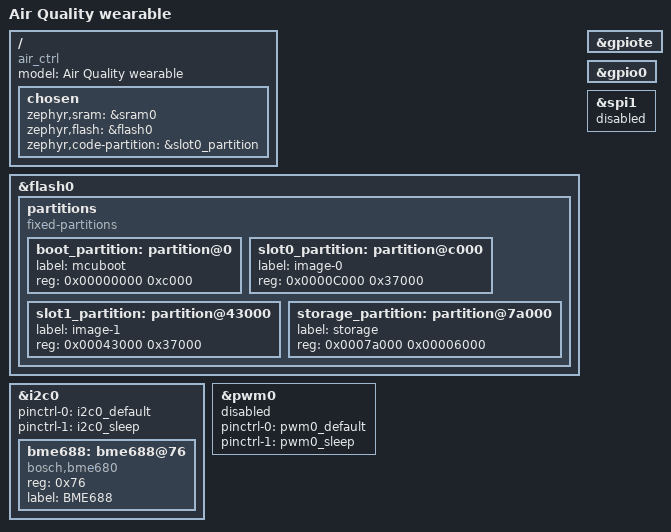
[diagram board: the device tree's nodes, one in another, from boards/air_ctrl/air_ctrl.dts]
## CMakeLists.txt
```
cmake_minimum_required(VERSION 3.20.0)

set(BOARD_ROOT ${CMAKE_CURRENT_SOURCE_DIR})

find_package(Zephyr REQUIRED HINTS $ENV{ZEPHYR_BASE})

project(air_ctrl)

# Application sources
target_sources(app PRIVATE
    src/main.c
    src/air_ctrl_bt.c
)

target_include_directories(app PRIVATE
    ${CMAKE_CURRENT_SOURCE_DIR}/src
)

if(CONFIG_AIR_CTRL_USE_BSEC)
    set(BSEC_INC_DIR ${CMAKE_CURRENT_SOURCE_DIR}/ext/algo/bsec_IAQ_Sel/inc)
    set(BSEC_CFG_DIR ${CMAKE_CURRENT_SOURCE_DIR}/ext/algo/bsec_IAQ_Sel/config/bme688/bme688_sel_33v_3s_28d)
    set(BSEC_SEL_C ${BSEC_CFG_DIR}/bsec_selectivity.c)
    set(BSEC_LIB ${CMAKE_CURRENT_SOURCE_DIR}/ext/algo/bsec_IAQ_Sel/bin/gcc/Cortex_M4F/libalgobsec.a)

    if(NOT EXISTS ${BSEC_LIB})
        message(FATAL_ERROR "CONFIG_AIR_CTRL_USE_BSEC is enabled but BSEC library was not found at: ${BSEC_LIB}")
    endif()

    target_sources(app PRIVATE
        src/air_ctrl_sensor_bsec.c
        ${BSEC_SEL_C}
    )

    target_include_directories(app PRIVATE
        ${BSEC_INC_DIR}
        ${BSEC_CFG_DIR}
    )

    target_link_libraries(app PRIVATE
        ${BSEC_LIB}
    )
else()
    target_sources(app PRIVATE
        src/air_ctrl_sensor_raw.c
    )
endif()
```

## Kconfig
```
source "Kconfig.zephyr"

menu "Air Ctrl"

config AIR_CTRL_USE_BSEC
	bool "Use Bosch BSEC library"
	default n

endmenu
```

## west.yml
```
manifest:
  version: "1.2"

  remotes:
    - name: zephyrproject-rtos
      url-base: https://github.com/zephyrproject-rtos

  projects:
    - name: zephyr
      remote: zephyrproject-rtos
      revision: v4.2.0
      path: zephyr
      import: true

  self:
    path: .
```

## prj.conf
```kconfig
# Debug console and logging
CONFIG_CONSOLE=y
CONFIG_LOG=y
CONFIG_STDOUT_CONSOLE=y
CONFIG_USE_SEGGER_RTT=y
CONFIG_RTT_CONSOLE=y
CONFIG_LOG_BACKEND_RTT=y
CONFIG_LOG_DEFAULT_LEVEL=3
CONFIG_CBPRINTF_FP_SUPPORT=y

CONFIG_SEGGER_RTT_BUFFER_SIZE_UP=8192
CONFIG_SEGGER_RTT_BUFFER_SIZE_DOWN=4096
CONFIG_LOG_MODE_DEFERRED=y
CONFIG_LOG_PROCESS_THREAD=y
CONFIG_LOG_PROCESS_THREAD_STACK_SIZE=2048

CONFIG_I2C=y

# Zephyr sensor subsystem + BME680 driver (used to read BME688 via compatible = "bosch,bme680")
CONFIG_SENSOR=y
CONFIG_BME680=y

# BME680 driver settings (compile-time)
CONFIG_BME680_TEMP_OVER_2X=y
CONFIG_BME680_PRESS_OVER_16X=y
CONFIG_BME680_HUMIDITY_OVER_1X=y
CONFIG_BME680_FILTER_OFF=y
CONFIG_BME680_HEATR_TEMP_LP=y
CONFIG_BME680_HEATR_DUR_LP=y

# FPU support and other stuff (required for BSEC library)
CONFIG_FPU=y
CONFIG_MAIN_STACK_SIZE=4096
CONFIG_PICOLIBC=y

# Bluetooth
CONFIG_BT=y
CONFIG_BT_PERIPHERAL=y
CONFIG_BT_DEVICE_NAME="air-ctrl"

CONFIG_SETTINGS=y
CONFIG_BT_SETTINGS=y

CONFIG_FLASH=y
CONFIG_FLASH_MAP=y
CONFIG_NVS=y
```

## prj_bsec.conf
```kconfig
CONFIG_AIR_CTRL_USE_BSEC=y
```

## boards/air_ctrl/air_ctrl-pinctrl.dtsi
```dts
&pinctrl {
	i2c0_default: i2c0_default {
		group1 {
			psels = <NRF_PSEL(TWIM_SDA, 0, 27)>,
			        <NRF_PSEL(TWIM_SCL, 0, 26)>;
		};
	};

	i2c0_sleep: i2c0_sleep {
		group1 {
			psels = <NRF_PSEL(TWIM_SDA, 0, 27)>,
			        <NRF_PSEL(TWIM_SCL, 0, 26)>;
			low-power-enable;
		};
	};

	pwm0_default: pwm0_default {
		group1 {
			psels = <NRF_PSEL(PWM_OUT0, 0, 10)>;
		};
	};

	pwm0_sleep: pwm0_sleep {
		group1 {
			psels = <NRF_PSEL(PWM_OUT0, 0, 10)>;
			low-power-enable;
		};
	};
};
```

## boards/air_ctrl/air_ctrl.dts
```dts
/dts-v1/;
#include <nordic/nrf52832_qfaa.dtsi>
#include "air_ctrl-pinctrl.dtsi"

/ {
	model = "Air Quality wearable";
	compatible = "air_ctrl";

	chosen {
		zephyr,sram = &sram0;
		zephyr,flash = &flash0;
		zephyr,code-partition = &slot0_partition;
	};
};

&flash0 {
	partitions {
		compatible = "fixed-partitions";
		#address-cells = <1>;
		#size-cells = <1>;

		boot_partition: partition@0 {
			label = "mcuboot";
			reg = <0x00000000 0xc000>;
		};

		slot0_partition: partition@c000 {
			label = "image-0";
			reg = <0x0000C000 0x37000>;
		};

		slot1_partition: partition@43000 {
			label = "image-1";
			reg = <0x00043000 0x37000>;
		};

		storage_partition: partition@7a000 {
			label = "storage";
			reg = <0x0007a000 0x00006000>;
		};
	};
};

&gpiote {
    status = "okay";
};

&gpio0 {
    status = "okay";
};

&i2c0 {
	status = "okay";
	pinctrl-0 = <&i2c0_default>;
	pinctrl-1 = <&i2c0_sleep>;
	pinctrl-names = "default", "sleep";

	bme688: bme688@76 {
		compatible = "bosch,bme680";
		reg = <0x76>;
		label = "BME688";
	};
};

&spi1 {
	status = "disabled";
};

&pwm0 {
	/* DISABLED: Pin conflict with backlight GPIO on P0.10 */
	status = "disabled";
	pinctrl-0 = <&pwm0_default>;
	pinctrl-1 = <&pwm0_sleep>;
	pinctrl-names = "default", "sleep";
};
```

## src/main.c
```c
#include <zephyr/kernel.h>
#include <zephyr/logging/log.h>
#include <zephyr/sys/util.h>

#include "air_ctrl_sensor.h"
#include "air_ctrl_bt.h"

LOG_MODULE_REGISTER(app, LOG_LEVEL_INF);

int main(void)
{
	int err;
	air_ctrl_sensor_data_t sensor_data;

	err = air_ctrl_bt_init();
	if (err) {
		LOG_ERR("Bluetooth init failed: %d", err);
	}

	LOG_INF("Air-ctrl device starting...");

	err = air_ctrl_sensor_init();
	if (err != 0) {
		LOG_ERR("Sensor integration init failed: %d", err);
		return 0;
	}

	#if IS_ENABLED(CONFIG_AIR_CTRL_USE_BSEC)
	LOG_INF("BSEC initialized, starting sensor loop...");
	LOG_INF("Note: IAQ accuracy will improve over time (needs ~5 min warm-up)");
	#else
	LOG_INF("Raw sensor mode initialized, starting sensor loop...");
	#endif

	while (true) {
		if (air_ctrl_sensor_run(&sensor_data)) {
			#if IS_ENABLED(CONFIG_AIR_CTRL_USE_BSEC)
			LOG_INF(
				"ts_ns,temp_raw_c,temp_comp_c,hum_raw_rh,hum_comp_rh,press_raw_pa,gas_raw_ohm,iaq,iaq_acc,static_iaq,co2_eq_ppm,breath_voc_eq_ppm,gas_pct,stabilized,run_in"
			);
			LOG_INF(
				"%lld,%.2f,%.2f,%.2f,%.2f,%.0f,%.0f,%.1f,%u,%.1f,%.0f,%.3f,%.1f,%u,%u",
				(long long)sensor_data.timestamp_ns,
				sensor_data.raw_temperature,
				sensor_data.temperature,
				sensor_data.raw_humidity,
				sensor_data.humidity,
				sensor_data.raw_pressure,
				sensor_data.raw_gas_resistance,
				sensor_data.iaq,
				sensor_data.iaq_accuracy,
				sensor_data.static_iaq,
				sensor_data.co2_equivalent,
				sensor_data.breath_voc_equivalent,
				sensor_data.gas_percentage,
				sensor_data.stabilization_status > 0.5f ? 1U : 0U,
				sensor_data.run_in_status > 0.5f ? 1U : 0U
			);
			#else
			LOG_INF("=== BME688 Raw Data ===");
			LOG_INF("  Temperature: %.2f \u00b0C", sensor_data.raw_temperature);
			LOG_INF("  Humidity: %.2f %%RH", sensor_data.raw_humidity);
			LOG_INF("  Pressure: %.2f hPa", sensor_data.raw_pressure / 100.0);
			LOG_INF("  Gas Resistance: %.0f Ohm", sensor_data.raw_gas_resistance);
			#endif

			(void)air_ctrl_bt_notify_sensor_data(&sensor_data);
		}

		k_sleep(K_MSEC(100));
	}
}
```

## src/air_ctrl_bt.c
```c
#include <zephyr/kernel.h>
#include <zephyr/settings/settings.h>
#include <zephyr/logging/log.h>
#include <zephyr/bluetooth/bluetooth.h>
#include <zephyr/bluetooth/conn.h>
#include <zephyr/bluetooth/gatt.h>
#include <zephyr/bluetooth/hci.h>
#include <zephyr/sys/byteorder.h>
#include <zephyr/sys/util.h>

#include <errno.h>
#include <limits.h>
#include <string.h>

#include "air_ctrl_bt.h"

LOG_MODULE_REGISTER(air_ctrl_bt, LOG_LEVEL_INF);

struct __packed air_ctrl_ble_sample_v1 {
	uint8_t version;
	uint8_t flags;
	uint16_t seq;
	uint32_t timestamp_ms;
	int16_t temp_c_x100;
	uint16_t hum_rh_x100;
	uint32_t gas_ohm;
	uint16_t iaq_x10;
	uint8_t iaq_acc;
	uint16_t co2_eq_ppm;
	uint16_t breath_voc_eq_ppb;
};

static struct bt_conn *default_conn;
static bool notify_enabled;
static uint16_t sample_seq;

static uint8_t last_sample[sizeof(struct air_ctrl_ble_sample_v1)];
static size_t last_sample_len;

#define BT_UUID_AIR_CTRL_SERVICE BT_UUID_DECLARE_128(BT_UUID_128_ENCODE(0x7f5f2cc2, 0x5d7a, 0x4a34, 0xa8c8, 0x1c7e3c01a7e1))

#define BT_UUID_AIR_CTRL_SAMPLE BT_UUID_DECLARE_128(BT_UUID_128_ENCODE(0x7f5f2cc3, 0x5d7a, 0x4a34, 0xa8c8, 0x1c7e3c01a7e1))

static void ccc_cfg_changed(const struct bt_gatt_attr *attr, uint16_t value)
{
	notify_enabled = (value == BT_GATT_CCC_NOTIFY);
}

static ssize_t read_sample(struct bt_conn *conn, const struct bt_gatt_attr *attr, void *buf,
			   uint16_t len, uint16_t offset)
{
	return bt_gatt_attr_read(conn, attr, buf, len, offset, last_sample, last_sample_len);
}

BT_GATT_SERVICE_DEFINE(air_ctrl_svc,
	BT_GATT_PRIMARY_SERVICE(BT_UUID_AIR_CTRL_SERVICE),
	BT_GATT_CHARACTERISTIC(BT_UUID_AIR_CTRL_SAMPLE,
			       BT_GATT_CHRC_READ | BT_GATT_CHRC_NOTIFY,
			       BT_GATT_PERM_READ, read_sample, NULL, NULL),
	BT_GATT_CCC(ccc_cfg_changed, BT_GATT_PERM_READ | BT_GATT_PERM_WRITE)
);

static const struct bt_data ad[] = {
	BT_DATA_BYTES(BT_DATA_FLAGS, (BT_LE_AD_GENERAL | BT_LE_AD_NO_BREDR)),
	BT_DATA(BT_DATA_NAME_COMPLETE, CONFIG_BT_DEVICE_NAME, sizeof(CONFIG_BT_DEVICE_NAME) - 1),
};

static void connected(struct bt_conn *conn, uint8_t err)
{
	if (err) {
		LOG_ERR("Connection failed err 0x%02x %s", err, bt_hci_err_to_str(err));
	} else {
		if (default_conn == NULL) {
			default_conn = bt_conn_ref(conn);
		}
		LOG_INF("Connected");
	}
}

static void disconnected(struct bt_conn *conn, uint8_t reason)
{
	if (default_conn != NULL) {
		bt_conn_unref(default_conn);
		default_conn = NULL;
	}

	notify_enabled = false;
	LOG_INF("Disconnected, reason 0x%02x %s", reason, bt_hci_err_to_str(reason));
}

BT_CONN_CB_DEFINE(conn_callbacks) = {
	.connected = connected,
	.disconnected = disconnected,
};

static void bt_ready(void)
{
	int err;

	LOG_INF("Bluetooth initialized");

	if (IS_ENABLED(CONFIG_SETTINGS)) {
		settings_load();
	}

	err = bt_le_adv_start(BT_LE_ADV_CONN_FAST_1, ad, ARRAY_SIZE(ad), NULL, 0);

	if (err) {
		LOG_ERR("Advertising failed to start (err %d)", err);
	} else {
		LOG_INF("Advertising successfully started");
	}
}

int air_ctrl_bt_init(void)
{
	int err;

	err = bt_enable(NULL);
	if (err) {
		LOG_ERR("Bluetooth init failed (err %d)", err);
		return err;
	}

	bt_ready();
	return 0;
}

bool air_ctrl_bt_is_connected(void)
{
	return default_conn != NULL;
}

static uint32_t ns_to_ms_u32(int64_t timestamp_ns)
{
	if (timestamp_ns <= 0) {
		return 0U;
	}

	return (uint32_t)(timestamp_ns / 1000000LL);
}

int air_ctrl_bt_notify_sensor_data(const air_ctrl_sensor_data_t *data)
{
	struct air_ctrl_ble_sample_v1 sample;
	uint16_t iaq_x10;
	uint32_t gas_ohm;
	uint16_t hum_x100;
	int16_t temp_x100;
	uint16_t co2_eq_ppm;
	uint16_t breath_voc_eq_ppb;

	if (data == NULL) {
		return -EINVAL;
	}

	if (!air_ctrl_bt_is_connected()) {
		return -ENOTCONN;
	}

	if (!notify_enabled) {
		return -EACCES;
	}

	gas_ohm = (data->raw_gas_resistance <= 0.0f) ? 0U : (uint32_t)data->raw_gas_resistance;

	temp_x100 = (int16_t)CLAMP((int32_t)(data->raw_temperature * 100.0f), INT16_MIN, INT16_MAX);
	hum_x100 = (uint16_t)CLAMP((int32_t)(data->raw_humidity * 100.0f), 0, UINT16_MAX);

	iaq_x10 = (data->iaq <= 0.0f) ? 0U : (uint16_t)CLAMP((int32_t)(data->iaq * 10.0f), 0, UINT16_MAX);
	co2_eq_ppm = (data->co2_equivalent <= 0.0f) ? 0U :
		(uint16_t)CLAMP((int32_t)(data->co2_equivalent + 0.5f), 0, UINT16_MAX);
	breath_voc_eq_ppb = (data->breath_voc_equivalent <= 0.0f) ? 0U :
		(uint16_t)CLAMP((int32_t)(data->breath_voc_equivalent * 1000.0f + 0.5f), 0, UINT16_MAX);

	sample.version = 2U;
	sample.flags = 0U;
	sample.seq = sys_cpu_to_le16(sample_seq++);
	sample.timestamp_ms = sys_cpu_to_le32(ns_to_ms_u32(data->timestamp_ns));
	sample.temp_c_x100 = (int16_t)sys_cpu_to_le16((uint16_t)temp_x100);
	sample.hum_rh_x100 = sys_cpu_to_le16(hum_x100);
	sample.gas_ohm = sys_cpu_to_le32(gas_ohm);
	sample.iaq_x10 = sys_cpu_to_le16(iaq_x10);
	sample.iaq_acc = data->iaq_accuracy;
	sample.co2_eq_ppm = sys_cpu_to_le16(co2_eq_ppm);
	sample.breath_voc_eq_ppb = sys_cpu_to_le16(breath_voc_eq_ppb);

	memcpy(last_sample, &sample, sizeof(sample));
	last_sample_len = sizeof(sample);

	return bt_gatt_notify(default_conn, &air_ctrl_svc.attrs[2], last_sample, last_sample_len);
}
```

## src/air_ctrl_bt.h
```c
#ifndef AIR_CTRL_BT_H
#define AIR_CTRL_BT_H

#include <stdbool.h>

#include "air_ctrl_sensor.h"

int air_ctrl_bt_init(void);

bool air_ctrl_bt_is_connected(void);

int air_ctrl_bt_notify_sensor_data(const air_ctrl_sensor_data_t *data);

#endif /* AIR_CTRL_BT_H */
```

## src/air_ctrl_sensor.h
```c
#ifndef AIR_CTRL_SENSOR_H_
#define AIR_CTRL_SENSOR_H_

#include <stdint.h>
#include <stdbool.h>

typedef struct {
    int64_t timestamp_ns;

    float raw_temperature;
    float raw_humidity;
    float raw_pressure;
    float raw_gas_resistance;

    float temperature;
    float humidity;

    float iaq;
    uint8_t iaq_accuracy;
    float static_iaq;
    float co2_equivalent;
    float breath_voc_equivalent;
    float gas_percentage;

    float stabilization_status;
    float run_in_status;
} air_ctrl_sensor_data_t;

int air_ctrl_sensor_init(void);

bool air_ctrl_sensor_run(air_ctrl_sensor_data_t *output);

int64_t air_ctrl_sensor_get_next_call_ns(void);

int64_t air_ctrl_sensor_get_timestamp_ns(void);

#endif /* AIR_CTRL_SENSOR_H_ */
```

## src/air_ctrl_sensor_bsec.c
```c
#include <zephyr/kernel.h>
#include <zephyr/logging/log.h>
#include <zephyr/device.h>
#include <zephyr/devicetree.h>
#include <zephyr/drivers/sensor.h>
#include <zephyr/settings/settings.h>

#include <errno.h>
#include <string.h>

#include "air_ctrl_sensor.h"
#include "bsec_interface.h"
#include "bsec_datatypes.h"
#include "bsec_selectivity.h"

LOG_MODULE_REGISTER(air_ctrl_sensor_bsec, LOG_LEVEL_INF);

#define BSEC_INSTANCE_SIZE 3272

#define BSEC_CHECK_INPUT(x, shift) (x & (1 << ((shift) - 1)))

static bsec_bme_settings_t bme_settings;

static float temp_offset = 0.0f;

static const struct device *const bme = DEVICE_DT_GET_ONE(bosch_bme680);

static uint8_t bsec_mem[BSEC_INSTANCE_SIZE] __aligned(4);
static void *bsec_instance = NULL;

static uint8_t bsec_work_buffer[BSEC_MAX_WORKBUFFER_SIZE] __aligned(4);

#define BSEC_STATE_SAVE_INTERVAL_NS (5LL * 60LL * 1000000000LL)

static uint8_t bsec_state_blob[BSEC_MAX_STATE_BLOB_SIZE] __aligned(4);
static size_t bsec_state_blob_len;
static bool bsec_state_blob_valid;
static int64_t bsec_last_state_save_ns;

static int bsec_settings_set(const char *name, size_t len, settings_read_cb read_cb, void *cb_arg)
{
	if (strcmp(name, "state") == 0) {
		if (len > sizeof(bsec_state_blob)) {
			return -EINVAL;
		}

		ssize_t rc = read_cb(cb_arg, bsec_state_blob, len);
		if (rc < 0) {
			return (int)rc;
		}

		bsec_state_blob_len = (size_t)rc;
		bsec_state_blob_valid = true;
		return 0;
	}

	return -ENOENT;
}

static struct settings_handler bsec_settings_handler = {
	.name = "air_ctrl/bsec",
	.h_set = bsec_settings_set,
};

static void bsec_state_save_if_needed(int64_t timestamp_ns)
{
	if (!IS_ENABLED(CONFIG_SETTINGS)) {
		return;
	}

	if (timestamp_ns < (bsec_last_state_save_ns + BSEC_STATE_SAVE_INTERVAL_NS)) {
		return;
	}

	uint32_t state_len = 0;
	memset(bsec_work_buffer, 0, sizeof(bsec_work_buffer));
	bsec_library_return_t bsec_status = bsec_get_state(bsec_instance, 0, bsec_state_blob,
						   sizeof(bsec_state_blob), bsec_work_buffer,
						   sizeof(bsec_work_buffer), &state_len);
	if (bsec_status != BSEC_OK) {
		LOG_ERR("bsec_get_state failed: %d", bsec_status);
		return;
	}

	int err = settings_save_one("air_ctrl/bsec/state", bsec_state_blob, state_len);
	if (err) {
		LOG_ERR("Failed to save BSEC state (err %d)", err);
		return;
	}

	bsec_last_state_save_ns = timestamp_ns;
	LOG_INF("Saved BSEC state (%u bytes)", state_len);
}

static bsec_sensor_configuration_t virtual_sensors[] = {
	{BSEC_SAMPLE_RATE_LP, BSEC_OUTPUT_IAQ},
	{BSEC_SAMPLE_RATE_LP, BSEC_OUTPUT_STATIC_IAQ},
	{BSEC_SAMPLE_RATE_LP, BSEC_OUTPUT_CO2_EQUIVALENT},
	{BSEC_SAMPLE_RATE_LP, BSEC_OUTPUT_BREATH_VOC_EQUIVALENT},
	{BSEC_SAMPLE_RATE_LP, BSEC_OUTPUT_RAW_TEMPERATURE},
	{BSEC_SAMPLE_RATE_LP, BSEC_OUTPUT_RAW_PRESSURE},
	{BSEC_SAMPLE_RATE_LP, BSEC_OUTPUT_RAW_HUMIDITY},
	{BSEC_SAMPLE_RATE_LP, BSEC_OUTPUT_RAW_GAS},
	{BSEC_SAMPLE_RATE_LP, BSEC_OUTPUT_STABILIZATION_STATUS},
	{BSEC_SAMPLE_RATE_LP, BSEC_OUTPUT_RUN_IN_STATUS},
	{BSEC_SAMPLE_RATE_LP, BSEC_OUTPUT_SENSOR_HEAT_COMPENSATED_TEMPERATURE},
	{BSEC_SAMPLE_RATE_LP, BSEC_OUTPUT_SENSOR_HEAT_COMPENSATED_HUMIDITY},
	{BSEC_SAMPLE_RATE_LP, BSEC_OUTPUT_GAS_PERCENTAGE},
};

#define NUM_VIRTUAL_SENSORS (sizeof(virtual_sensors) / sizeof(virtual_sensors[0]))

int64_t air_ctrl_sensor_get_timestamp_ns(void)
{
	return k_ticks_to_ns_near64(k_uptime_ticks());
}

static bool process_data(float temperature_c, float humidity_percent, float pressure_pa,
			 float gas_ohm, int64_t timestamp_ns, air_ctrl_sensor_data_t *output)
{
	bsec_input_t inputs[BSEC_MAX_PHYSICAL_SENSOR];
	bsec_output_t outputs[BSEC_NUMBER_OUTPUTS];
	uint8_t n_inputs = 0;
	uint8_t n_outputs = BSEC_NUMBER_OUTPUTS;
	bsec_library_return_t status;

	if (!bme_settings.trigger_measurement || bme_settings.op_mode == 0) {
		return false;
	}

	if (BSEC_CHECK_INPUT(bme_settings.process_data, BSEC_INPUT_TEMPERATURE)) {
		inputs[n_inputs].sensor_id = BSEC_INPUT_HEATSOURCE;
		inputs[n_inputs].signal = temp_offset;
		inputs[n_inputs].time_stamp = timestamp_ns;
		n_inputs++;

		inputs[n_inputs].sensor_id = BSEC_INPUT_TEMPERATURE;
		inputs[n_inputs].signal = temperature_c;
		inputs[n_inputs].time_stamp = timestamp_ns;
		n_inputs++;
	}

	if (BSEC_CHECK_INPUT(bme_settings.process_data, BSEC_INPUT_HUMIDITY)) {
		inputs[n_inputs].sensor_id = BSEC_INPUT_HUMIDITY;
		inputs[n_inputs].signal = humidity_percent;
		inputs[n_inputs].time_stamp = timestamp_ns;
		n_inputs++;
	}

	if (BSEC_CHECK_INPUT(bme_settings.process_data, BSEC_INPUT_PRESSURE)) {
		inputs[n_inputs].sensor_id = BSEC_INPUT_PRESSURE;
		inputs[n_inputs].signal = pressure_pa;
		inputs[n_inputs].time_stamp = timestamp_ns;
		n_inputs++;
	}

	if (BSEC_CHECK_INPUT(bme_settings.process_data, BSEC_INPUT_GASRESISTOR)) {
		inputs[n_inputs].sensor_id = BSEC_INPUT_GASRESISTOR;
		inputs[n_inputs].signal = gas_ohm;
		inputs[n_inputs].time_stamp = timestamp_ns;
		n_inputs++;
	}

	if (BSEC_CHECK_INPUT(bme_settings.process_data, BSEC_INPUT_PROFILE_PART)) {
		inputs[n_inputs].sensor_id = BSEC_INPUT_PROFILE_PART;
		inputs[n_inputs].signal = 0.0f;
		inputs[n_inputs].time_stamp = timestamp_ns;
		n_inputs++;
	}

	if (BSEC_CHECK_INPUT(bme_settings.process_data, BSEC_INPUT_DISABLE_BASELINE_TRACKER)) {
		inputs[n_inputs].sensor_id = BSEC_INPUT_DISABLE_BASELINE_TRACKER;
		inputs[n_inputs].signal = 0.0f;
		inputs[n_inputs].time_stamp = timestamp_ns;
		n_inputs++;
	}

	if (n_inputs == 0) {
		return false;
	}

	LOG_DBG("BSEC inputs: n=%d T=%.2f H=%.2f P=%.0f Gas=%.0f", n_inputs, (double)temperature_c,
		(double)humidity_percent, (double)pressure_pa, (double)gas_ohm);

	memset(outputs, 0, sizeof(outputs));
	status = bsec_do_steps(bsec_instance, inputs, n_inputs, outputs, &n_outputs);

	if (status != BSEC_OK) {
		LOG_ERR("bsec_do_steps failed: %d", status);
		return false;
	}

	LOG_DBG("bsec_do_steps: n_outputs=%d", n_outputs);

	memset(output, 0, sizeof(air_ctrl_sensor_data_t));

	for (uint8_t i = 0; i < n_outputs; i++) {
		switch (outputs[i].sensor_id) {
		case BSEC_OUTPUT_RAW_TEMPERATURE:
			output->raw_temperature = outputs[i].signal;
			break;
		case BSEC_OUTPUT_RAW_HUMIDITY:
			output->raw_humidity = outputs[i].signal;
			break;
		case BSEC_OUTPUT_RAW_PRESSURE:
			output->raw_pressure = outputs[i].signal;
			break;
		case BSEC_OUTPUT_RAW_GAS:
			output->raw_gas_resistance = outputs[i].signal;
			break;
		case BSEC_OUTPUT_SENSOR_HEAT_COMPENSATED_TEMPERATURE:
			output->temperature = outputs[i].signal;
			break;
		case BSEC_OUTPUT_SENSOR_HEAT_COMPENSATED_HUMIDITY:
			output->humidity = outputs[i].signal;
			break;
		case BSEC_OUTPUT_IAQ:
			output->iaq = outputs[i].signal;
			output->iaq_accuracy = outputs[i].accuracy;
			break;
		case BSEC_OUTPUT_STATIC_IAQ:
			output->static_iaq = outputs[i].signal;
			break;
		case BSEC_OUTPUT_CO2_EQUIVALENT:
			output->co2_equivalent = outputs[i].signal;
			break;
		case BSEC_OUTPUT_BREATH_VOC_EQUIVALENT:
			output->breath_voc_equivalent = outputs[i].signal;
			break;
		case BSEC_OUTPUT_GAS_PERCENTAGE:
			output->gas_percentage = outputs[i].signal;
			break;
		case BSEC_OUTPUT_STABILIZATION_STATUS:
			output->stabilization_status = outputs[i].signal;
			break;
		case BSEC_OUTPUT_RUN_IN_STATUS:
			output->run_in_status = outputs[i].signal;
			break;
		default:
			break;
		}
		output->timestamp_ns = outputs[i].time_stamp;
	}

	return (n_outputs > 0);
}

static bool measure_and_process(air_ctrl_sensor_data_t *output)
{
	struct sensor_value temp;
	struct sensor_value pressure;
	struct sensor_value humidity;
	struct sensor_value gas;
	bool need_gas = BSEC_CHECK_INPUT(bme_settings.process_data, BSEC_INPUT_GASRESISTOR);

	if (sensor_sample_fetch(bme) < 0) {
		LOG_ERR("BME680 sample fetch failed");
		return false;
	}

	if (sensor_channel_get(bme, SENSOR_CHAN_AMBIENT_TEMP, &temp) ||
	    sensor_channel_get(bme, SENSOR_CHAN_PRESS, &pressure) ||
	    sensor_channel_get(bme, SENSOR_CHAN_HUMIDITY, &humidity)) {
		LOG_ERR("BME680 channel read failed");
		return false;
	}

	if (need_gas) {
		if (sensor_channel_get(bme, SENSOR_CHAN_GAS_RES, &gas)) {
			LOG_ERR("BME680 gas channel read failed");
			return false;
		}
	} else {
		gas.val1 = 0;
		gas.val2 = 0;
	}

	const int64_t timestamp_ns = air_ctrl_sensor_get_timestamp_ns();

	const float temperature_c = (float)sensor_value_to_double(&temp);
	const float humidity_percent = (float)sensor_value_to_double(&humidity);
	const float pressure_pa = (float)(sensor_value_to_double(&pressure) * 1000.0);
	const float gas_ohm = (float)gas.val1;

	return process_data(temperature_c, humidity_percent, pressure_pa, gas_ohm, timestamp_ns, output);
}

int air_ctrl_sensor_init(void)
{
	bsec_library_return_t bsec_status;
	bsec_version_t version;
	bsec_sensor_configuration_t required_sensors[BSEC_MAX_PHYSICAL_SENSOR];
	uint8_t n_required = BSEC_MAX_PHYSICAL_SENSOR;
	int err;

	LOG_INF("Initializing BSEC integration...");

	bsec_instance = (void *)bsec_mem;

	if (!device_is_ready(bme)) {
		LOG_ERR("BME680 not ready");
		return -ENODEV;
	}

	bsec_get_version(bsec_instance, &version);
	LOG_INF("BSEC version: %d.%d.%d.%d", version.major, version.minor, version.major_bugfix,
		version.minor_bugfix);

	bsec_status = bsec_init(bsec_instance);
	if (bsec_status != BSEC_OK) {
		LOG_ERR("bsec_init failed: %d", bsec_status);
		return -EIO;
	}
	LOG_INF("BSEC initialized");

	memset(bsec_work_buffer, 0, sizeof(bsec_work_buffer));
	bsec_status = bsec_set_configuration(bsec_instance, bsec_config_selectivity, BSEC_MAX_PROPERTY_BLOB_SIZE,
					 bsec_work_buffer, BSEC_MAX_WORKBUFFER_SIZE);
	if (bsec_status != BSEC_OK) {
		LOG_ERR("bsec_set_configuration failed: %d", bsec_status);
		return -EIO;
	}

	if (IS_ENABLED(CONFIG_SETTINGS)) {
		err = settings_register(&bsec_settings_handler);
		if (err) {
			LOG_ERR("settings_register failed (err %d)", err);
		} else {
			bsec_state_blob_valid = false;
			bsec_state_blob_len = 0;
			err = settings_load_subtree("air_ctrl/bsec");
			if (err) {
				LOG_ERR("settings_load_subtree failed (err %d)", err);
			}

			if (bsec_state_blob_valid && bsec_state_blob_len > 0) {
				memset(bsec_work_buffer, 0, sizeof(bsec_work_buffer));
				bsec_status = bsec_set_state(bsec_instance, bsec_state_blob, bsec_state_blob_len,
							     bsec_work_buffer, sizeof(bsec_work_buffer));
				if (bsec_status != BSEC_OK) {
					LOG_ERR("bsec_set_state failed: %d", bsec_status);
				} else {
					LOG_INF("Restored BSEC state (%u bytes)", (uint32_t)bsec_state_blob_len);
				}
			}
		}
	}

	bsec_status = bsec_update_subscription(bsec_instance, virtual_sensors, NUM_VIRTUAL_SENSORS,
					 required_sensors, &n_required);
	if (bsec_status != BSEC_OK) {
		LOG_ERR("bsec_update_subscription failed: %d", bsec_status);
		return -EIO;
	}
	LOG_INF("BSEC subscribed to %d virtual sensors, requires %d physical sensors", NUM_VIRTUAL_SENSORS,
		n_required);

	memset(&bme_settings, 0, sizeof(bme_settings));
	bsec_last_state_save_ns = air_ctrl_sensor_get_timestamp_ns();

	LOG_INF("BSEC integration initialized successfully");

	return 0;
}

int64_t air_ctrl_sensor_get_next_call_ns(void)
{
	return bme_settings.next_call;
}

bool air_ctrl_sensor_run(air_ctrl_sensor_data_t *output)
{
	int64_t timestamp_ns;
	bsec_library_return_t bsec_status;

	if (output == NULL) {
		return false;
	}

	timestamp_ns = air_ctrl_sensor_get_timestamp_ns();

	if (timestamp_ns < bme_settings.next_call) {
		return false;
	}

	bsec_status = bsec_sensor_control(bsec_instance, timestamp_ns, &bme_settings);
	if (bsec_status != BSEC_OK) {
		LOG_ERR("bsec_sensor_control failed: %d", bsec_status);
		return false;
	}

	if (bme_settings.op_mode == 0) {
		return false;
	}

	if (bme_settings.trigger_measurement) {
		bool ok = measure_and_process(output);
		if (ok) {
			bsec_state_save_if_needed(timestamp_ns);
		}
		return ok;
	}

	return false;
}
```

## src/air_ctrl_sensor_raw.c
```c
#include <zephyr/kernel.h>
#include <zephyr/logging/log.h>
#include <zephyr/device.h>
#include <zephyr/devicetree.h>
#include <zephyr/drivers/sensor.h>

#include <errno.h>
#include <string.h>

#include "air_ctrl_sensor.h"

LOG_MODULE_REGISTER(air_ctrl_sensor, LOG_LEVEL_DBG);

#define RAW_SAMPLE_PERIOD_NS (3LL * 1000000000LL)

static const struct device *const bme = DEVICE_DT_GET_ONE(bosch_bme680);

static int64_t next_call_ns;

int64_t air_ctrl_sensor_get_timestamp_ns(void)
{
	return k_ticks_to_ns_near64(k_uptime_ticks());
}

int air_ctrl_sensor_init(void)
{
	if (!device_is_ready(bme)) {
		LOG_ERR("BME680 not ready");
		return -ENODEV;
	}

	next_call_ns = 0;
	LOG_INF("Raw BME688 mode initialized");
	return 0;
}

int64_t air_ctrl_sensor_get_next_call_ns(void)
{
	return next_call_ns;
}

bool air_ctrl_sensor_run(air_ctrl_sensor_data_t *output)
{
	struct sensor_value temp;
	struct sensor_value pressure;
	struct sensor_value humidity;
	struct sensor_value gas;
	int64_t timestamp_ns;

	if (output == NULL) {
		return false;
	}

	timestamp_ns = air_ctrl_sensor_get_timestamp_ns();
	if (timestamp_ns < next_call_ns) {
		return false;
	}

	if (sensor_sample_fetch(bme) < 0) {
		LOG_ERR("BME680 sample fetch failed");
		next_call_ns = timestamp_ns + RAW_SAMPLE_PERIOD_NS;
		return false;
	}

	if (sensor_channel_get(bme, SENSOR_CHAN_AMBIENT_TEMP, &temp) ||
		sensor_channel_get(bme, SENSOR_CHAN_PRESS, &pressure) ||
		sensor_channel_get(bme, SENSOR_CHAN_HUMIDITY, &humidity) ||
		sensor_channel_get(bme, SENSOR_CHAN_GAS_RES, &gas)) {
		LOG_ERR("BME680 channel read failed");
		next_call_ns = timestamp_ns + RAW_SAMPLE_PERIOD_NS;
		return false;
	}

	memset(output, 0, sizeof(*output));

	output->timestamp_ns = timestamp_ns;
	output->raw_temperature = (float)sensor_value_to_double(&temp);
	output->raw_humidity = (float)sensor_value_to_double(&humidity);
	output->raw_pressure = (float)(sensor_value_to_double(&pressure) * 1000.0);
	output->raw_gas_resistance = (float)gas.val1;

	output->temperature = output->raw_temperature;
	output->humidity = output->raw_humidity;

	next_call_ns = timestamp_ns + RAW_SAMPLE_PERIOD_NS;
	return true;
}
```
